# CY8C4A45LQI_483 register map
File version: 0.1
PSoC Analog Coprocessor
Registers are 32-bit, read-write, no defined reset value unless marked. A register's access mark holds for its fields unless they carry their own. Offsets are from the block's base; lines under a group give offsets from that group; [hi:lo] are bit positions; {n}, {i} and the like mark numbered series; 'fields as' and 'values as' point back to an identical list; <NAME> marks a mode.

## Memory map
0x00000000 SPI — Serial Communication Block
0x00000000 I2C — Serial Communication Block
0x00000000 VDAC_2_UAB
0x00000000 VDAC_2_OUTBUFFER — OpAmp
0x00000000 ADC_1
0x00000000 VDAC_1_UAB
0x00000000 VDAC_1_OUTBUFFER — OpAmp
0x00000000 Timer_1
0x00000000 Timer_2
0x00000000 PWM_2
0x00000000 PWM_1
0x40000000 DMAC — DMAC Registers

## VDAC_2_OUTBUFFER — OpAmp
Base 0x00000000
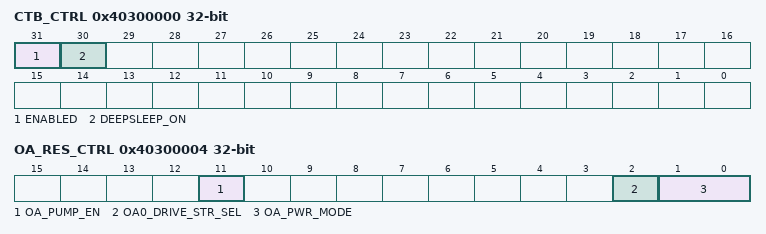
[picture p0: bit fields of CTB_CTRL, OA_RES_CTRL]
0x40300000 CTB_CTRL — Global CTB IP and power control
  [31] ENABLED — Selects component behavior in DeepSleep power mode
    0=DISABLE (CTB IP disabled (put analog in power down, open all switches)); 1=ENABLE (CTB IP enabledCTB IP enabled)
  [30] DEEPSLEEP_ON — Selects component behavior in DeepSleep power mode
    0=DISABLE (CTB IP disabled off during DeepSleep power mode); 1=ENABLE (CTB IP remains enabled during DeepSleep power mode (if ENABLED=1))
0x40300004 OA_RES_CTRL — Opamp and resistor control
  [11] OA_PUMP_EN — Selects pump
    0=DISABLE (Pump disabled); 1=ENABLE (Pump enabled)
  [2] OA0_DRIVE_STR_SEL — Opamp output strenght select
    0=Cy1x (Internal only); 1=Cy10x (Output to pin)
  [1:0] OA_PWR_MODE — Selects power for opamp
    0=OFF; 1=LOW (Low power); 2=MED (Medium power); 3=HIGH (High power)
0x40300F08 OA_COMP_TRIM — Opamp Compenation Capacitor Trim
  [1:0] OA_COMP_TRIM
    1=HIGH_SPEED; 2=BALANCED; 3=HIGH_STABILITY

## VDAC_1_OUTBUFFER — OpAmp
Base 0x00000000
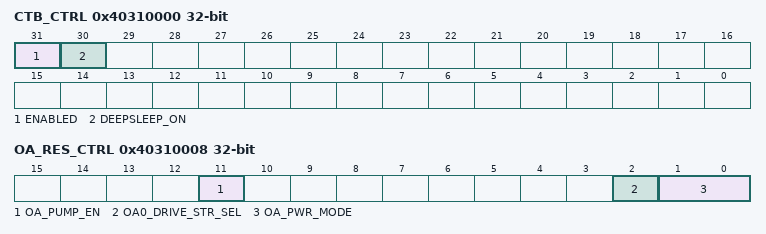
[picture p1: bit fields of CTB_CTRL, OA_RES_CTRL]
0x40310000 CTB_CTRL — Global CTB IP and power control
  [31] ENABLED — Selects component behavior in DeepSleep power mode
    0=DISABLE (CTB IP disabled (put analog in power down, open all switches)); 1=ENABLE (CTB IP enabledCTB IP enabled)
  [30] DEEPSLEEP_ON — Selects component behavior in DeepSleep power mode
    0=DISABLE (CTB IP disabled off during DeepSleep power mode); 1=ENABLE (CTB IP remains enabled during DeepSleep power mode (if ENABLED=1))
0x40310008 OA_RES_CTRL — Opamp and resistor control
  [11] OA_PUMP_EN — Selects pump
    0=DISABLE (Pump disabled); 1=ENABLE (Pump enabled)
  [2] OA0_DRIVE_STR_SEL — Opamp output strenght select
    0=Cy1x (Internal only); 1=Cy10x (Output to pin)
  [1:0] OA_PWR_MODE — Selects power for opamp
    0=OFF; 1=LOW (Low power); 2=MED (Medium power); 3=HIGH (High power)
0x40310F14 OA_COMP_TRIM — Opamp Compenation Capacitor Trim
  [1:0] OA_COMP_TRIM
    1=HIGH_SPEED; 2=BALANCED; 3=HIGH_STABILITY

## Timer_1
Base 0x00000000
0x40010108 COUNTER — Current counter value
0x4001010C CC — Compare / capture value
0x40010110 CC_BUF — Compare / capture buffer value
0x40010114 PERIOD — Period value
0x40010118 PERIOD_BUF — Period buffer value

## Timer_2
Base 0x00000000
0x40010188 COUNTER — Current counter value
0x4001018C CC — Compare / capture value
0x40010190 CC_BUF — Compare / capture buffer value
0x40010194 PERIOD — Period value
0x40010198 PERIOD_BUF — Period buffer value

## PWM_2
Base 0x00000000
0x40010148 COUNTER — Current counter value
0x4001014C CC — Compare / capture value
0x40010150 CC_BUF — Compare / capture buffer value
0x40010154 PERIOD — Period value
0x40010158 PERIOD_BUF — Period buffer value

## PWM_1
Base 0x00000000
0x400101C8 COUNTER — Current counter value
0x400101CC CC — Compare / capture value
0x400101D0 CC_BUF — Compare / capture buffer value
0x400101D4 PERIOD — Period value
0x400101D8 PERIOD_BUF — Period buffer value
